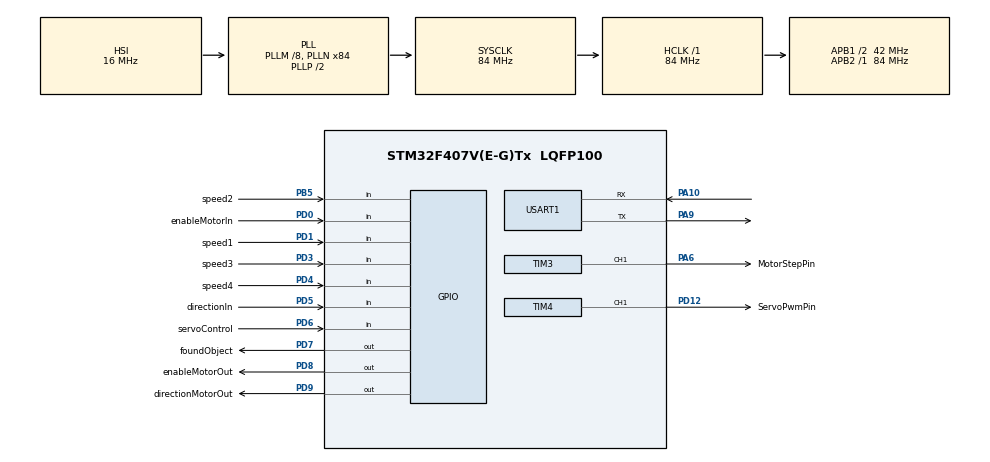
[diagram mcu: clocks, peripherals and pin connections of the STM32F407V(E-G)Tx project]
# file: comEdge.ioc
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Mcu.Family=STM32F4
Mcu.Name=STM32F407V(E-G)Tx
Mcu.Package=LQFP100
NVIC.PriorityGroup=NVIC_PRIORITYGROUP_4
PA10.Mode=Asynchronous
PA10.Signal=USART1_RX
PA13.Mode=Serial_Wire
PA13.Signal=SYS_JTMS-SWDIO
PA14.Mode=Serial_Wire
PA14.Signal=SYS_JTCK-SWCLK
PA6.GPIO_Label=MotorStepPin
PA6.Signal=S_TIM3_CH1
PA9.Mode=Asynchronous
PA9.Signal=USART1_TX
PB5.GPIO_Label=speed2
PB5.GPIO_PuPd=GPIO_PULLDOWN
PB5.Signal=GPIO_Input
PD0.GPIO_Label=enableMotorIn
PD0.GPIO_PuPd=GPIO_PULLDOWN
PD0.Signal=GPIO_Input
PD1.GPIO_Label=speed1
PD1.GPIO_PuPd=GPIO_PULLDOWN
PD1.Signal=GPIO_Input
PD12.GPIO_Label=ServoPwmPin
PD12.Signal=S_TIM4_CH1
PD3.GPIO_Label=speed3
PD3.GPIO_PuPd=GPIO_PULLDOWN
PD3.Signal=GPIO_Input
PD4.GPIO_Label=speed4
PD4.GPIO_PuPd=GPIO_PULLDOWN
PD4.Signal=GPIO_Input
PD5.GPIO_Label=directionIn
PD5.GPIO_PuPd=GPIO_PULLDOWN
PD5.Signal=GPIO_Input
PD6.GPIO_Label=servoControl
PD6.GPIO_PuPd=GPIO_PULLDOWN
PD6.Signal=GPIO_Input
PD7.GPIO_Label=foundObject
PD7.GPIO_ModeDefaultOutputPP=GPIO_MODE_OUTPUT_OD
PD7.GPIO_PuPd=GPIO_NOPULL
PD7.PinState=GPIO_PIN_SET
PD7.Signal=GPIO_Output
PD8.GPIO_Label=enableMotorOut
PD8.Signal=GPIO_Output
PD9.GPIO_Label=directionMotorOut
PD9.Signal=GPIO_Output
ProjectManager.HeapSize=0x200
ProjectManager.StackSize=0x400
ProjectManager.TargetToolchain=STM32CubeIDE
RCC.48MHZClocksFreq_Value=42000000
RCC.AHBFreq_Value=84000000
RCC.APB1CLKDivider=RCC_HCLK_DIV2
RCC.APB1Freq_Value=42000000
RCC.APB1TimFreq_Value=84000000
RCC.APB2Freq_Value=84000000
RCC.APB2TimFreq_Value=84000000
RCC.CortexFreq_Value=84000000
RCC.HCLKFreq_Value=84000000
RCC.HSE_VALUE=25000000
RCC.HSI_VALUE=16000000
RCC.LSE_VALUE=32768
RCC.PLLM=8
RCC.PLLN=84
RCC.SYSCLKFreq_VALUE=84000000
RCC.SYSCLKSource=RCC_SYSCLKSOURCE_PLLCLK
RCC.VCOOutputFreq_Value=168000000
SH.S_TIM3_CH1.0=TIM3_CH1,PWM Generation1 CH1
SH.S_TIM4_CH1.0=TIM4_CH1,PWM Generation1 CH1
TIM3.AutoReloadPreload=TIM_AUTORELOAD_PRELOAD_ENABLE
TIM3.Channel-PWM\ Generation1\ CH1=TIM_CHANNEL_1
TIM3.Period=2999
TIM3.Prescaler=27
TIM3.Pulse-PWM\ Generation1\ CH1=1500
TIM4.AutoReloadPreload=TIM_AUTORELOAD_PRELOAD_ENABLE
TIM4.Channel-PWM\ Generation1\ CH1=TIM_CHANNEL_1
TIM4.Period=19999
TIM4.Prescaler=83
USART1.VirtualMode=VM_ASYNC
VP_TIM3_VS_ClockSourceINT.Mode=Internal
board=custom

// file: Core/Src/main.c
/* USER CODE BEGIN Header */
/**
  ******************************************************************************
  * @file           : main.c
  * @brief          : Main program body
  ******************************************************************************
  * @attention
  *
  * Copyright (c) 2026 STMicroelectronics.
  * All rights reserved.
  *
  * This software is licensed under terms that can be found in the LICENSE file
  * in the root directory of this software component.
  * If no LICENSE file comes with this software, it is provided AS-IS.
  *
  ******************************************************************************
  */
/* USER CODE END Header */
#include "main.h"

/* USER CODE BEGIN Includes */
#include "bsp.h"
/* USER CODE END Includes */

TIM_HandleTypeDef htim3;
TIM_HandleTypeDef htim4;

UART_HandleTypeDef huart1;

void SystemClock_Config(void);
static void MX_GPIO_Init(void);
static void MX_TIM3_Init(void);
static void MX_TIM4_Init(void);
static void MX_USART1_UART_Init(void);

int main(void)
{

  /* MCU Configuration--------------------------------------------------------*/

  /* Reset of all peripherals, Initializes the Flash interface and the Systick. */
  HAL_Init();

  /* Configure the system clock */
  SystemClock_Config();

  /* Initialize all configured peripherals */
  MX_GPIO_Init();
  MX_TIM3_Init();
  MX_TIM4_Init();
  MX_USART1_UART_Init();
  /* USER CODE BEGIN 2 */
  BSP_InitAPP();
  /* USER CODE END 2 */

  /* Infinite loop */
  while (1)
  {

  }
}

void SystemClock_Config(void)
{
  RCC_OscInitTypeDef RCC_OscInitStruct = {0};
  RCC_ClkInitTypeDef RCC_ClkInitStruct = {0};

  /** Configure the main internal regulator output voltage
  */
  __HAL_RCC_PWR_CLK_ENABLE();
  __HAL_PWR_VOLTAGESCALING_CONFIG(PWR_REGULATOR_VOLTAGE_SCALE1);

  /** Initializes the RCC Oscillators according to the specified parameters
  * in the RCC_OscInitTypeDef structure.
  */
  RCC_OscInitStruct.OscillatorType = RCC_OSCILLATORTYPE_HSI;
  RCC_OscInitStruct.HSIState = RCC_HSI_ON;
  RCC_OscInitStruct.HSICalibrationValue = RCC_HSICALIBRATION_DEFAULT;
  RCC_OscInitStruct.PLL.PLLState = RCC_PLL_ON;
  RCC_OscInitStruct.PLL.PLLSource = RCC_PLLSOURCE_HSI;
  RCC_OscInitStruct.PLL.PLLM = 8;
  RCC_OscInitStruct.PLL.PLLN = 84;
  RCC_OscInitStruct.PLL.PLLP = RCC_PLLP_DIV2;
  RCC_OscInitStruct.PLL.PLLQ = 4;
  if (HAL_RCC_OscConfig(&RCC_OscInitStruct) != HAL_OK)
  {
    Error_Handler();
  }

  /** Initializes the CPU, AHB and APB buses clocks
  */
  RCC_ClkInitStruct.ClockType = RCC_CLOCKTYPE_HCLK|RCC_CLOCKTYPE_SYSCLK
                              |RCC_CLOCKTYPE_PCLK1|RCC_CLOCKTYPE_PCLK2;
  RCC_ClkInitStruct.SYSCLKSource = RCC_SYSCLKSOURCE_PLLCLK;
  RCC_ClkInitStruct.AHBCLKDivider = RCC_SYSCLK_DIV1;
  RCC_ClkInitStruct.APB1CLKDivider = RCC_HCLK_DIV2;
  RCC_ClkInitStruct.APB2CLKDivider = RCC_HCLK_DIV1;

  if (HAL_RCC_ClockConfig(&RCC_ClkInitStruct, FLASH_LATENCY_2) != HAL_OK)
  {
    Error_Handler();
  }
}

static void MX_TIM3_Init(void)
{

  TIM_ClockConfigTypeDef sClockSourceConfig = {0};
  TIM_MasterConfigTypeDef sMasterConfig = {0};
  TIM_OC_InitTypeDef sConfigOC = {0};

  htim3.Instance = TIM3;
  htim3.Init.Prescaler = 27;
  htim3.Init.CounterMode = TIM_COUNTERMODE_UP;
  htim3.Init.Period = 2999;
  htim3.Init.ClockDivision = TIM_CLOCKDIVISION_DIV1;
  htim3.Init.AutoReloadPreload = TIM_AUTORELOAD_PRELOAD_ENABLE;
  if (HAL_TIM_Base_Init(&htim3) != HAL_OK)
  {
    Error_Handler();
  }
  sClockSourceConfig.ClockSource = TIM_CLOCKSOURCE_INTERNAL;
  if (HAL_TIM_ConfigClockSource(&htim3, &sClockSourceConfig) != HAL_OK)
  {
    Error_Handler();
  }
  if (HAL_TIM_PWM_Init(&htim3) != HAL_OK)
  {
    Error_Handler();
  }
  sMasterConfig.MasterOutputTrigger = TIM_TRGO_RESET;
  sMasterConfig.MasterSlaveMode = TIM_MASTERSLAVEMODE_DISABLE;
  if (HAL_TIMEx_MasterConfigSynchronization(&htim3, &sMasterConfig) != HAL_OK)
  {
    Error_Handler();
  }
  sConfigOC.OCMode = TIM_OCMODE_PWM1;
  sConfigOC.Pulse = 1500;
  sConfigOC.OCPolarity = TIM_OCPOLARITY_HIGH;
  sConfigOC.OCFastMode = TIM_OCFAST_DISABLE;
  if (HAL_TIM_PWM_ConfigChannel(&htim3, &sConfigOC, TIM_CHANNEL_1) != HAL_OK)
  {
    Error_Handler();
  }
  HAL_TIM_MspPostInit(&htim3);

}

static void MX_TIM4_Init(void)
{

  TIM_MasterConfigTypeDef sMasterConfig = {0};
  TIM_OC_InitTypeDef sConfigOC = {0};

  htim4.Instance = TIM4;
  htim4.Init.Prescaler = 83;
  htim4.Init.CounterMode = TIM_COUNTERMODE_UP;
  htim4.Init.Period = 19999;
  htim4.Init.ClockDivision = TIM_CLOCKDIVISION_DIV1;
  htim4.Init.AutoReloadPreload = TIM_AUTORELOAD_PRELOAD_ENABLE;
  if (HAL_TIM_PWM_Init(&htim4) != HAL_OK)
  {
    Error_Handler();
  }
  sMasterConfig.MasterOutputTrigger = TIM_TRGO_RESET;
  sMasterConfig.MasterSlaveMode = TIM_MASTERSLAVEMODE_DISABLE;
  if (HAL_TIMEx_MasterConfigSynchronization(&htim4, &sMasterConfig) != HAL_OK)
  {
    Error_Handler();
  }
  sConfigOC.OCMode = TIM_OCMODE_PWM1;
  sConfigOC.Pulse = 0;
  sConfigOC.OCPolarity = TIM_OCPOLARITY_HIGH;
  sConfigOC.OCFastMode = TIM_OCFAST_DISABLE;
  if (HAL_TIM_PWM_ConfigChannel(&htim4, &sConfigOC, TIM_CHANNEL_1) != HAL_OK)
  {
    Error_Handler();
  }
  HAL_TIM_MspPostInit(&htim4);

}

static void MX_USART1_UART_Init(void)
{

  huart1.Instance = USART1;
  huart1.Init.BaudRate = 115200;
  huart1.Init.WordLength = UART_WORDLENGTH_8B;
  huart1.Init.StopBits = UART_STOPBITS_1;
  huart1.Init.Parity = UART_PARITY_NONE;
  huart1.Init.Mode = UART_MODE_TX_RX;
  huart1.Init.HwFlowCtl = UART_HWCONTROL_NONE;
  huart1.Init.OverSampling = UART_OVERSAMPLING_16;
  if (HAL_UART_Init(&huart1) != HAL_OK)
  {
    Error_Handler();
  }

}

static void MX_GPIO_Init(void)
{
  GPIO_InitTypeDef GPIO_InitStruct = {0};

  /* GPIO Ports Clock Enable */
  __HAL_RCC_GPIOA_CLK_ENABLE();
  __HAL_RCC_GPIOD_CLK_ENABLE();
  __HAL_RCC_GPIOB_CLK_ENABLE();

  /*Configure GPIO pin Output Level */
  HAL_GPIO_WritePin(GPIOD, enableMotorOut_Pin|directionMotorOut_Pin, GPIO_PIN_RESET);

  /*Configure GPIO pin Output Level */
  HAL_GPIO_WritePin(foundObject_GPIO_Port, foundObject_Pin, GPIO_PIN_SET);

  /*Configure GPIO pins : enableMotorOut_Pin directionMotorOut_Pin */
  GPIO_InitStruct.Pin = enableMotorOut_Pin|directionMotorOut_Pin;
  GPIO_InitStruct.Mode = GPIO_MODE_OUTPUT_PP;
  GPIO_InitStruct.Pull = GPIO_NOPULL;
  GPIO_InitStruct.Speed = GPIO_SPEED_FREQ_LOW;
  HAL_GPIO_Init(GPIOD, &GPIO_InitStruct);

  /*Configure GPIO pins : enableMotorIn_Pin speed1_Pin speed3_Pin speed4_Pin
                           directionIn_Pin servoControl_Pin */
  GPIO_InitStruct.Pin = enableMotorIn_Pin|speed1_Pin|speed3_Pin|speed4_Pin
                          |directionIn_Pin|servoControl_Pin;
  GPIO_InitStruct.Mode = GPIO_MODE_INPUT;
  GPIO_InitStruct.Pull = GPIO_PULLDOWN;
  HAL_GPIO_Init(GPIOD, &GPIO_InitStruct);

  /*Configure GPIO pin : foundObject_Pin */
  GPIO_InitStruct.Pin = foundObject_Pin;
  GPIO_InitStruct.Mode = GPIO_MODE_OUTPUT_OD;
  GPIO_InitStruct.Pull = GPIO_NOPULL;
  GPIO_InitStruct.Speed = GPIO_SPEED_FREQ_LOW;
  HAL_GPIO_Init(foundObject_GPIO_Port, &GPIO_InitStruct);

  /*Configure GPIO pin : speed2_Pin */
  GPIO_InitStruct.Pin = speed2_Pin;
  GPIO_InitStruct.Mode = GPIO_MODE_INPUT;
  GPIO_InitStruct.Pull = GPIO_PULLDOWN;
  HAL_GPIO_Init(speed2_GPIO_Port, &GPIO_InitStruct);

}

void Error_Handler(void)
{
  __disable_irq();
  while (1)
  {
  }
}
